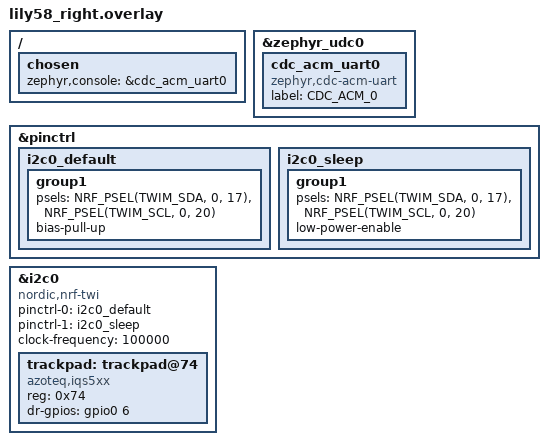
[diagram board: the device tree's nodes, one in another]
/* config/lily58_right.overlay */
#include <dt-bindings/pinctrl/nrf-pinctrl.h>

/ {
    chosen {
        zephyr,console = &cdc_acm_uart0;
    };
};

&zephyr_udc0 {
    status = "okay";
    cdc_acm_uart0: cdc_acm_uart0 {
        compatible = "zephyr,cdc-acm-uart";
        label = "CDC_ACM_0";
    };
};

/* 🔥 소프트웨어로 I2C 풀업 저항 켜기 🔥 */
&pinctrl {
    i2c0_default: i2c0_default {
        group1 {
            psels = <NRF_PSEL(TWIM_SDA, 0, 17)>,
                    <NRF_PSEL(TWIM_SCL, 0, 20)>;
            bias-pull-up; /* 👈 이 한 줄이 핵심입니다! */
        };
    };
    i2c0_sleep: i2c0_sleep {
        group1 {
            psels = <NRF_PSEL(TWIM_SDA, 0, 17)>,
                    <NRF_PSEL(TWIM_SCL, 0, 20)>;
            low-power-enable;
        };
    };
};

&i2c0 {
    status = "okay";
    compatible = "nordic,nrf-twi";
    pinctrl-0 = <&i2c0_default>;
    pinctrl-1 = <&i2c0_sleep>;
    pinctrl-names = "default", "sleep";
    clock-frequency = <100000>; /* 안정성을 위해 속도 100kHz로 하향 */

    trackpad: trackpad@74 {
        compatible = "azoteq,iqs5xx";
        status = "okay";
        reg = <0x74>;
        /* 가짜 인터럽트 핀 (에러 방지용) */
        dr-gpios = <&gpio0 6 (GPIO_ACTIVE_HIGH | GPIO_PULL_DOWN)>;
    };
};
